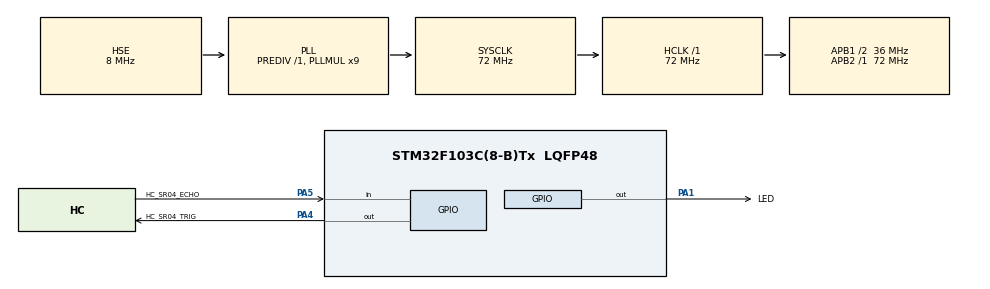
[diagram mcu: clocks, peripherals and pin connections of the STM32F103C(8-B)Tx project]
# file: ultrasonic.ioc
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Mcu.Family=STM32F1
Mcu.Name=STM32F103C(8-B)Tx
Mcu.Package=LQFP48
NVIC.PriorityGroup=NVIC_PRIORITYGROUP_4
NVIC.TIM2_IRQn=true\:0\:0\:false\:false\:true\:true\:true
PA1.GPIO_Label=LED
PA1.Signal=GPIO_Output
PA13.Mode=Serial_Wire
PA13.Signal=SYS_JTMS-SWDIO
PA14.Mode=Serial_Wire
PA14.Signal=SYS_JTCK-SWCLK
PA4.GPIO_Label=HC_SR04_TRIG
PA4.Signal=GPIO_Output
PA5.GPIO_Label=HC_SR04_ECHO
PA5.GPIO_PuPd=GPIO_PULLDOWN
PA5.Signal=GPIO_Input
PD0-OSC_IN.Mode=HSE-External-Clock-Source
PD0-OSC_IN.Signal=RCC_OSC_IN
PD1-OSC_OUT.Mode=HSE-External-Clock-Source
PD1-OSC_OUT.Signal=RCC_OSC_OUT
ProjectManager.HeapSize=0x200
ProjectManager.StackSize=0x400
ProjectManager.TargetToolchain=Makefile
RCC.AHBFreq_Value=72000000
RCC.APB1CLKDivider=RCC_HCLK_DIV2
RCC.APB1Freq_Value=36000000
RCC.APB1TimFreq_Value=72000000
RCC.APB2Freq_Value=72000000
RCC.APB2TimFreq_Value=72000000
RCC.HCLKFreq_Value=72000000
RCC.PLLMUL=RCC_PLL_MUL9
RCC.PLLSourceVirtual=RCC_PLLSOURCE_HSE
RCC.SYSCLKFreq_VALUE=72000000
RCC.SYSCLKSource=RCC_SYSCLKSOURCE_PLLCLK
RCC.USBFreq_Value=72000000
TIM2.AutoReloadPreload=TIM_AUTORELOAD_PRELOAD_DISABLE
TIM2.Period=1000 - 1
TIM2.Prescaler=72 - 1
VP_TIM2_VS_ClockSourceINT.Mode=Internal
board=custom

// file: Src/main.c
/* USER CODE BEGIN Header */
/**
  ******************************************************************************
  * @file           : main.c
  * @brief          : Main program body
  ******************************************************************************
  * @attention
  *
  * <h2><center>&copy; Copyright (c) 2019 STMicroelectronics.
  * All rights reserved.</center></h2>
  *
  * This software component is licensed by ST under BSD 3-Clause license,
  * the "License"; You may not use this file except in compliance with the
  * License. You may obtain a copy of the License at:
  *                        opensource.org/licenses/BSD-3-Clause
  *
  ******************************************************************************
  */
/* USER CODE END Header */

#include "main.h"
#include "tim.h"
#include "gpio.h"

/* USER CODE BEGIN PM */
#define ARRAYSIZE(a)  (sizeof(a) / sizeof((a)[0]))

/* USER CODE END PM */

/* USER CODE BEGIN PV */
static __IO uint32_t g_timerMs = 0;

/* USER CODE END PV */

void SystemClock_Config(void);

/* USER CODE BEGIN 0 */
static void DelayUs(uint32_t us)
{
  if (us > 0)
  {
    uint32_t start = SysTick->VAL;
    while (SysTick->VAL + us * 72 >= start);
  }
}

static uint32_t HC_SR04_Read(void)
{
  uint32_t startMs = 0;
  GPIO_PinState echo = GPIO_PIN_RESET;

  HAL_GPIO_WritePin(HC_SR04_TRIG_GPIO_Port, HC_SR04_TRIG_Pin, GPIO_PIN_SET);
  DelayUs(20);
  HAL_GPIO_WritePin(HC_SR04_TRIG_GPIO_Port, HC_SR04_TRIG_Pin, GPIO_PIN_RESET);
  DelayUs(20);

  startMs = HAL_GetTick();
  do
  {
    echo = HAL_GPIO_ReadPin(HC_SR04_ECHO_GPIO_Port, HC_SR04_ECHO_Pin);
  } while ((GPIO_PIN_RESET == echo) && (HAL_GetTick() < startMs + 1));

  if (GPIO_PIN_RESET == echo)
  {
    return UINT32_MAX;
  }
  else
  {
    uint32_t startMs = 0;
    uint32_t startUs = 0;
    uint32_t timeUs = 0;

    startMs = HAL_GetTick();
    startUs = SysTick->VAL;
    while (GPIO_PIN_SET == HAL_GPIO_ReadPin(HC_SR04_ECHO_Pin, HC_SR04_ECHO_Pin));
    timeUs = (HAL_GetTick() - startMs) * 1000 + (startUs - SysTick->VAL) / 72;

    return timeUs * 170 / 1000;
  }
}

static uint32_t HC_SR04_GetDistance(void)
{
  static uint32_t distances[] = {0, 0, 0, 0, 0};
  static size_t current = UINT32_MAX;
  size_t minIdx = 0;
  size_t maxIdx = 0;
  uint32_t sum = 0;

  if (current >= ARRAYSIZE(distances))
  {
    for (size_t i = 0; i < ARRAYSIZE(distances); ++i)
    {
      distances[i] = HC_SR04_Read();
    }
    current = 0;
  }
  else
  {
    distances[current] = HC_SR04_Read();
    if (++current >= ARRAYSIZE(distances))
    {
      current = 0;
    }
  }

  minIdx = 0;
  maxIdx = 0;
  for (size_t i = 0; i < ARRAYSIZE(distances); ++i)
  {
    if (distances[i] < distances[minIdx])
    {
      minIdx = i;
    }
    else
    {
      if (distances[i] > distances[maxIdx])
      {
        maxIdx = i;
      }
    }
  }
  if (minIdx == maxIdx)
  {
    ++maxIdx;
  }

  sum = 0;
  for (size_t i = 0; i < ARRAYSIZE(distances); ++i)
  {
    if ((i != minIdx) && (i != maxIdx))
    {
      sum += distances[i];
    }
  }

  return sum / (ARRAYSIZE(distances) - 2);
}

/* USER CODE END 0 */

int main(void)
{

  /* MCU Configuration--------------------------------------------------------*/

  /* Reset of all peripherals, Initializes the Flash interface and the Systick. */
  HAL_Init();

  /* Configure the system clock */
  SystemClock_Config();

  /* Initialize all configured peripherals */
  MX_GPIO_Init();
  MX_TIM2_Init();
  /* USER CODE BEGIN 2 */
  HAL_TIM_Base_Start_IT(&htim2);

  /* USER CODE END 2 */

  /* Infinite loop */
  while (1)
  {

    /* USER CODE BEGIN 3 */
    if (HC_SR04_GetDistance() < 100)
    {
      HAL_GPIO_WritePin(LED_GPIO_Port, LED_Pin, GPIO_PIN_RESET);
    }
    else
    {
      HAL_GPIO_WritePin(LED_GPIO_Port, LED_Pin, GPIO_PIN_SET);
    }

    HAL_Delay(100);
  }
  /* USER CODE END 3 */
}

void SystemClock_Config(void)
{
  RCC_OscInitTypeDef RCC_OscInitStruct = {0};
  RCC_ClkInitTypeDef RCC_ClkInitStruct = {0};

  /** Initializes the CPU, AHB and APB busses clocks
  */
  RCC_OscInitStruct.OscillatorType = RCC_OSCILLATORTYPE_HSE;
  RCC_OscInitStruct.HSEState = RCC_HSE_BYPASS;
  RCC_OscInitStruct.HSEPredivValue = RCC_HSE_PREDIV_DIV1;
  RCC_OscInitStruct.HSIState = RCC_HSI_ON;
  RCC_OscInitStruct.PLL.PLLState = RCC_PLL_ON;
  RCC_OscInitStruct.PLL.PLLSource = RCC_PLLSOURCE_HSE;
  RCC_OscInitStruct.PLL.PLLMUL = RCC_PLL_MUL9;
  if (HAL_RCC_OscConfig(&RCC_OscInitStruct) != HAL_OK)
  {
    Error_Handler();
  }
  /** Initializes the CPU, AHB and APB busses clocks
  */
  RCC_ClkInitStruct.ClockType = RCC_CLOCKTYPE_HCLK|RCC_CLOCKTYPE_SYSCLK
                              |RCC_CLOCKTYPE_PCLK1|RCC_CLOCKTYPE_PCLK2;
  RCC_ClkInitStruct.SYSCLKSource = RCC_SYSCLKSOURCE_PLLCLK;
  RCC_ClkInitStruct.AHBCLKDivider = RCC_SYSCLK_DIV1;
  RCC_ClkInitStruct.APB1CLKDivider = RCC_HCLK_DIV2;
  RCC_ClkInitStruct.APB2CLKDivider = RCC_HCLK_DIV1;

  if (HAL_RCC_ClockConfig(&RCC_ClkInitStruct, FLASH_LATENCY_2) != HAL_OK)
  {
    Error_Handler();
  }
}

/* USER CODE BEGIN 4 */
void HAL_TIM_PeriodElapsedCallback(TIM_HandleTypeDef *tim_baseHandle)
{
  // if (tim_baseHandle->Instance == htim2.Instance)
  {
    if (++g_timerMs >= 1000000)
    {
      g_timerMs = 0;
    }
  }
}

/* USER CODE END 4 */

void Error_Handler(void)
{
}

/************************ (C) COPYRIGHT STMicroelectronics *****END OF FILE****/
